VERSION ""

NS_ :

BS_:

BU_: Vector__XXX

BO_ 0 BMS_ERROR: 8 Vector__XXX
SG_ BMS_ERROR : 0|64@1+ (1,0) [0|1.84467440737096E019] "" Vector__XXX

BO_ 1 BMS_HEARTBEAT: 1 Vector__XXX
SG_ BMS_HEARTBEAT : 0|8@1+ (1,0) [0|255] "" Vector__XXX

BO_ 2 BMS_ACCUMULATOR_STATUS: 3 Vector__XXX
SG_ BMS_ACCUMULATOR_STATUS : 0|24@1+ (1,0) [0|16777215] "" Vector__XXX

BO_ 4 BMS_ACCUMULATOR_REGEN_POWER_LIMI: 4 Vector__XXX
SG_ BMS_ACCUMULATOR_REGEN_POWER_LIMI : 0|32@1+ (1,0) [0|4294967295] "" Vector__XXX

BO_ 5 BMS_ACCUMULATOR_SOC: 4 Vector__XXX
SG_ BMS_ACCUMULATOR_SOC : 0|32@1+ (1,0) [0|4294967295] "" Vector__XXX

BO_ 3 BMS_ACCUMULATOR_DISCHARGE_POWER: 8 Vector__XXX
SG_ BMS_ACCUMULATOR_DISCHARGE_POWER : 0|64@1+ (1,0) [0|1.84467440737096E019] "" Vector__XXX

BO_ 6 BMS_TURN_ON_ALL_FETS: 1 Vector__XXX
SG_ BMS_TURN_ON_ALL_FETS : 0|8@1+ (1,0) [0|255] "" Vector__XXX

BO_ 7 BMS_CELL_VOLTAGE: 4 Vector__XXX
SG_ BMS_CELL_VOLTAGE : 0|32@1+ (1,0) [0|4294967295] "" Vector__XXX

BO_ 8 BMS_BALANCE_MOSFET: 5 Vector__XXX
SG_ BMS_BALANCE_MOSFET : 0|40@1+ (1,0) [0|1099511627775] "" Vector__XXX

BO_ 9 BMS_LATCH_RESET: 1 Vector__XXX
SG_ BMS_LATCH_RESET : 0|8@1+ (1,0) [0|255] "" Vector__XXX

BO_ 10 BMS_MOTOR_REENABLE: 1 Vector__XXX
SG_ BMS_MOTOR_REENABLE : 0|8@1+ (1,0) [0|255] "" Vector__XXX

BO_ 11 BMS_AIR_SHUTDOWN_ERROR: 6 Vector__XXX
SG_ BMS_AIR_SHUTDOWN_ERROR : 0|48@1+ (1,0) [0|281474976710655] "" Vector__XXX

BO_ 32 DCM_ERROR: 8 Vector__XXX
SG_ DCM_ERROR : 0|64@1+ (1,0) [0|1.84467440737096E019] "" Vector__XXX

BO_ 33 DCM_HEARTBEAT: 1 Vector__XXX
SG_ DCM_HEARTBEAT : 0|8@1+ (1,0) [0|255] "" Vector__XXX

BO_ 34 DCM_LEFT_SLIP_RATIO: 4 Vector__XXX
SG_ DCM_LEFT_SLIP_RATIO : 0|32@1+ (1,0) [0|4294967295] "" Vector__XXX

BO_ 35 DCM_RIGHT_SLIP_RATIO: 4 Vector__XXX
SG_ DCM_RIGHT_SLIP_RATIO : 0|32@1+ (1,0) [0|4294967295] "" Vector__XXX

BO_ 36 DCM_LEFT_MOTOR_OUTPUT: 4 Vector__XXX
SG_ DCM_LEFT_MOTOR_OUTPUT : 0|32@1+ (1,0) [0|4294967295] "" Vector__XXX

BO_ 37 DCM_RIGHT_MOTOR_OUTPUT: 4 Vector__XXX
SG_ DCM_RIGHT_MOTOR_OUTPUT : 0|32@1+ (1,0) [0|4294967295] "" Vector__XXX

BO_ 38 DCM_LEFT_SLIP_ERROR: 4 Vector__XXX
SG_ DCM_LEFT_SLIP_ERROR : 0|32@1+ (1,0) [0|4294967295] "" Vector__XXX

BO_ 39 DCM_RIGHT_SLIP_ERROR: 4 Vector__XXX
SG_ DCM_RIGHT_SLIP_ERROR : 0|32@1+ (1,0) [0|4294967295] "" Vector__XXX

BO_ 64 FSM_ERROR: 8 Vector__XXX
SG_ FSM_ERROR : 0|64@1+ (1,0) [0|1.84467440737096E019] "" Vector__XXX

BO_ 65 FSM_HEARTBEAT: 1 Vector__XXX
SG_ FSM_HEARTBEAT : 0|8@1+ (1,0) [0|255] "" Vector__XXX

BO_ 66 FSM_BRAKE_APPS: 4 Vector__XXX
SG_ FSM_BRAKE_APPS : 0|32@1+ (1,0) [0|4294967295] "" Vector__XXX

BO_ 67 FSM_STEERING_ANGLE: 4 Vector__XXX
SG_ FSM_STEERING_ANGLE : 0|32@1+ (1,0) [0|4294967295] "" Vector__XXX

BO_ 68 FSM_LEFT_WHEEL_SPEED: 4 Vector__XXX
SG_ FSM_LEFT_WHEEL_SPEED : 0|32@1+ (1,0) [0|4294967295] "" Vector__XXX

BO_ 69 FSM_RIGHT_WHEEL_SPEED: 4 Vector__XXX
SG_ FSM_RIGHT_WHEEL_SPEED : 0|32@1+ (1,0) [0|4294967295] "" Vector__XXX

BO_ 96 PDM_ERROR: 8 Vector__XXX
SG_ PDM_ERROR : 0|64@1+ (1,0) [0|1.84467440737096E019] "" Vector__XXX

BO_ 97 PDM_HEARTBEAT: 1 Vector__XXX
SG_ PDM_HEARTBEAT : 0|8@1+ (1,0) [0|255] "" Vector__XXX

BO_ 98 PDM_STARTUP_STATUS: 1 Vector__XXX
SG_ PDM_STARTUP_STATUS : 0|8@1+ (1,0) [0|255] "" Vector__XXX

BO_ 128 MOTOR_SHUTDOWN_ERROR: 6 Vector__XXX
SG_ MOTOR_SHUTDOWN_ERROR : 0|48@1+ (1,0) [0|281474976710655] "" Vector__XXX

BO_ 400 LEFT_TORQUE_REQUEST_TX: 3 Vector__XXX
SG_ LEFT_TORQUE_REQUEST_TX : 0|24@1+ (1,0) [0|16777215] "" Vector__XXX

BO_ 401 RIGHT_TORQUE_REQUEST_TX: 3 Vector__XXX
SG_ RIGHT_TORQUE_REQUEST_TX : 0|24@1+ (1,0) [0|16777215] "" Vector__XXX

BO_ 528 LEFT_TORQUE_REQUEST_RX: 3 Vector__XXX
SG_ LEFT_TORQUE_REQUEST_RX : 0|24@1+ (1,0) [0|16777215] "" Vector__XXX

BO_ 529 RIGHT_TORQUE_REQUEST_RX: 3 Vector__XXX
SG_ RIGHT_TORQUE_REQUEST_RX : 0|24@1+ (1,0) [0|16777215] "" Vector__XXX

BO_ 1024 DEMO_1_DOUBLE_NUCLEO_TX_STDID: 8 Vector__XXX
SG_ Double : 0|64@1- (1,0) [-1.7E308|1.7E308] "" Vector__XXX

BO_ 1025 DEMO_1_DOUBLE_NUCLEO_RX_STDID: 8 Vector__XXX
SG_ Double : 0|64@1- (1,0) [-1.7E308|1.7E308] "" Vector__XXX

BO_ 1026 DEMO_2_FLOAT_NUCLEO_TX_STDID: 8 Vector__XXX
SG_ Float_1 : 0|32@1- (1,0) [-3.4E038|3.4E038] "" Vector__XXX
SG_ Float_2 : 32|32@1- (1,0) [-3.4E038|3.4E038] "" Vector__XXX

BO_ 1027 DEMO_2_FLOAT_NUCLEO_RX_STDID: 8 Vector__XXX
SG_ Float_1 : 0|32@1- (1,0) [-3.4E038|3.4E038] "" Vector__XXX
SG_ Float_2 : 32|32@1- (1,0) [-3.4E038|3.4E038] "" Vector__XXX

BO_ 1028 DEMO_2_UINT32_NUCLEO_TX_STDID: 8 Vector__XXX
SG_ Uint32_1 : 0|32@1+ (1,0) [0|4294967295] "" Vector__XXX
SG_ Uint32_2 : 32|32@1+ (1,0) [0|4294967295] "" Vector__XXX

BO_ 1029 DEMO_2_UINT32_NUCLEO_RX_STDID: 8 Vector__XXX
SG_ Unit32_1 : 0|32@1+ (1,0) [0|4294967295] "" Vector__XXX
SG_ Unit32_2 : 32|32@1+ (1,0) [0|4294967295] "" Vector__XXX

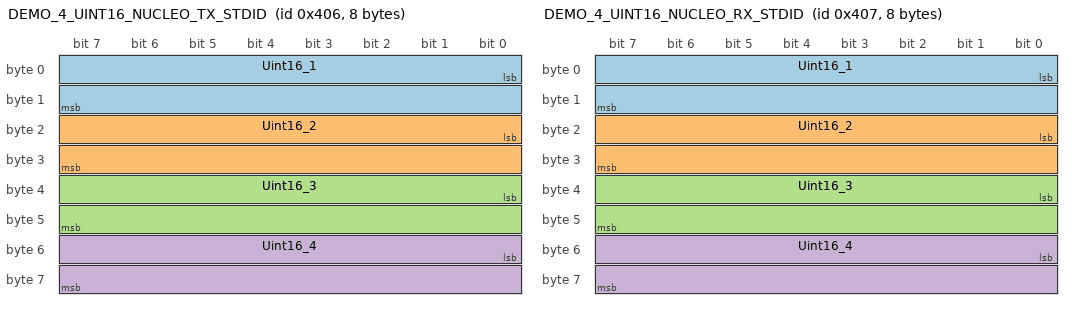
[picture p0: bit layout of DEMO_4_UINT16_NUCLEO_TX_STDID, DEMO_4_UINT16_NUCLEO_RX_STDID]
BO_ 1030 DEMO_4_UINT16_NUCLEO_TX_STDID: 8 Vector__XXX
SG_ Uint16_1 : 0|16@1+ (1,0) [0|65535] "" Vector__XXX
SG_ Uint16_2 : 16|16@1+ (1,0) [0|65535] "" Vector__XXX
SG_ Uint16_3 : 32|16@1+ (1,0) [0|65535] "" Vector__XXX
SG_ Uint16_4 : 48|16@1+ (1,0) [0|65535] "" Vector__XXX

BO_ 1031 DEMO_4_UINT16_NUCLEO_RX_STDID: 8 Vector__XXX
SG_ Uint16_1 : 0|16@1+ (1,0) [0|65535] "" Vector__XXX
SG_ Uint16_2 : 16|16@1+ (1,0) [0|65535] "" Vector__XXX
SG_ Uint16_3 : 32|16@1+ (1,0) [0|65535] "" Vector__XXX
SG_ Uint16_4 : 48|16@1+ (1,0) [0|65535] "" Vector__XXX

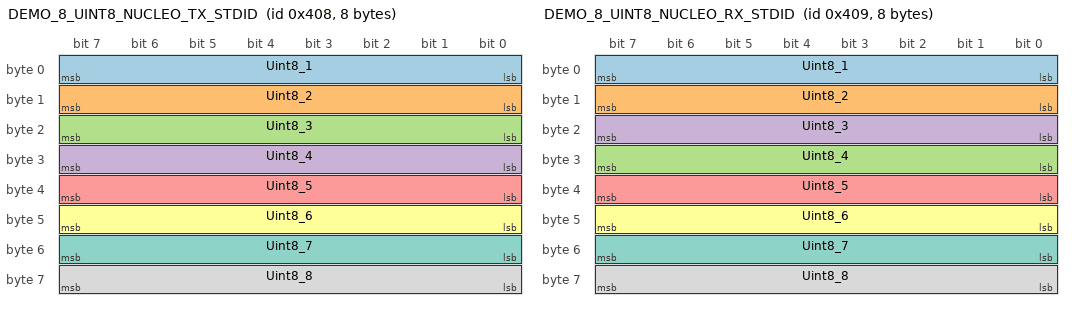
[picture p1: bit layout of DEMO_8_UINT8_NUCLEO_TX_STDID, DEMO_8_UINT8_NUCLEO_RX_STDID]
BO_ 1032 DEMO_8_UINT8_NUCLEO_TX_STDID: 8 Vector__XXX
SG_ Uint8_1 : 0|8@1+ (1,0) [0|255] "" Vector__XXX
SG_ Uint8_2 : 8|8@1+ (1,0) [0|255] "" Vector__XXX
SG_ Uint8_3 : 16|8@1+ (1,0) [0|255] "" Vector__XXX
SG_ Uint8_4 : 24|8@1+ (1,0) [0|255] "" Vector__XXX
SG_ Uint8_5 : 32|8@1+ (1,0) [0|255] "" Vector__XXX
SG_ Uint8_6 : 40|8@1+ (1,0) [0|255] "" Vector__XXX
SG_ Uint8_7 : 48|8@1+ (1,0) [0|255] "" Vector__XXX
SG_ Uint8_8 : 56|8@1+ (1,0) [0|255] "" Vector__XXX

BO_ 1033 DEMO_8_UINT8_NUCLEO_RX_STDID: 8 Vector__XXX
SG_ Uint8_1 : 0|8@1+ (1,0) [0|255] "" Vector__XXX
SG_ Uint8_2 : 8|8@1+ (1,0) [0|255] "" Vector__XXX
SG_ Uint8_4 : 24|8@1+ (1,0) [0|255] "" Vector__XXX
SG_ Uint8_3 : 16|8@1+ (1,0) [0|255] "" Vector__XXX
SG_ Uint8_5 : 32|8@1+ (1,0) [0|255] "" Vector__XXX
SG_ Uint8_6 : 40|8@1+ (1,0) [0|255] "" Vector__XXX
SG_ Uint8_7 : 48|8@1+ (1,0) [0|255] "" Vector__XXX
SG_ Uint8_8 : 56|8@1+ (1,0) [0|255] "" Vector__XXX

BO_ 1034 DEMO_2_INT32_NUCLEO_TX_STDID: 8 Vector__XXX
SG_ Int32_1 : 0|32@1- (1,0) [-2147483648|2147483647] "" Vector__XXX
SG_ Int32_2 : 32|32@1- (1,0) [-2147483648|2147483647] "" Vector__XXX

BO_ 1035 DEMO_2_INT32_NUCLEO_RX_STDID: 8 Vector__XXX
SG_ Int32_1 : 0|32@1- (1,0) [-2147483648|2147483647] "" Vector__XXX
SG_ Int32_2 : 32|32@1- (1,0) [-2147483648|2147483647] "" Vector__XXX

BA_DEF_  "BusType" STRING ;

BA_DEF_DEF_  "BusType" "CAN";

SIG_VALTYPE_ 1024 Double : 2;
SIG_VALTYPE_ 1025 Double : 2;
SIG_VALTYPE_ 1026 Float_1 : 1;
SIG_VALTYPE_ 1026 Float_2 : 1;
SIG_VALTYPE_ 1027 Float_1 : 1;
SIG_VALTYPE_ 1027 Float_2 : 1;
